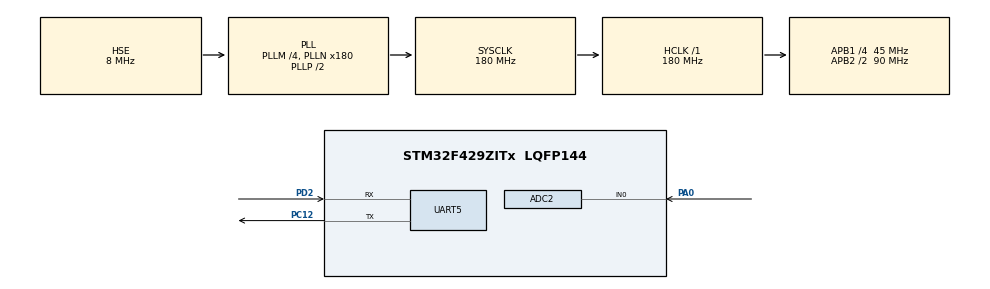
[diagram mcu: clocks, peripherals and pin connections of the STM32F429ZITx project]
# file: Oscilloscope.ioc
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ADC1.Channel-0\#ChannelRegularConversion=ADC_CHANNEL_VREFINT
ADC1.NbrOfConversionFlag=1
ADC1.Rank-0\#ChannelRegularConversion=1
ADC1.Resolution=ADC_RESOLUTION_10B
ADC1.SamplingTime-0\#ChannelRegularConversion=ADC_SAMPLETIME_3CYCLES
ADC1.master=1
ADC2.Channel-0\#ChannelRegularConversion=ADC_CHANNEL_0
ADC2.ContinuousConvMode=ENABLE
ADC2.DMAContinuousRequests=ENABLE
ADC2.NbrOfConversionFlag=1
ADC2.Rank-0\#ChannelRegularConversion=1
ADC2.Resolution=ADC_RESOLUTION_8B
ADC2.SamplingTime-0\#ChannelRegularConversion=ADC_SAMPLETIME_3CYCLES
Dma.ADC2.0.Direction=DMA_PERIPH_TO_MEMORY
Dma.ADC2.0.FIFOMode=DMA_FIFOMODE_DISABLE
Dma.ADC2.0.Instance=DMA2_Stream2
Dma.ADC2.0.MemDataAlignment=DMA_MDATAALIGN_HALFWORD
Dma.ADC2.0.MemInc=DMA_MINC_ENABLE
Dma.ADC2.0.Mode=DMA_CIRCULAR
Dma.ADC2.0.PeriphDataAlignment=DMA_PDATAALIGN_HALFWORD
Dma.ADC2.0.PeriphInc=DMA_PINC_DISABLE
Dma.ADC2.0.Priority=DMA_PRIORITY_LOW
Dma.Request0=ADC2
Mcu.Family=STM32F4
Mcu.Name=STM32F429ZITx
Mcu.Package=LQFP144
NVIC.DMA2_Stream2_IRQn=true\:0\:0\:false\:false\:true\:false\:true
NVIC.PriorityGroup=NVIC_PRIORITYGROUP_4
PA0/WKUP.Signal=ADCx_IN0
PC12.Mode=Asynchronous
PC12.Signal=UART5_TX
PD2.Mode=Asynchronous
PD2.Signal=UART5_RX
PH0/OSC_IN.Mode=HSE-External-Oscillator
PH0/OSC_IN.Signal=RCC_OSC_IN
PH1/OSC_OUT.Mode=HSE-External-Oscillator
PH1/OSC_OUT.Signal=RCC_OSC_OUT
ProjectManager.HeapSize=0x200
ProjectManager.StackSize=0x400
ProjectManager.TargetToolchain=MDK-ARM V5.27
RCC.48MHZClocksFreq_Value=90000000
RCC.AHBFreq_Value=180000000
RCC.APB1CLKDivider=RCC_HCLK_DIV4
RCC.APB1Freq_Value=45000000
RCC.APB1TimFreq_Value=90000000
RCC.APB2CLKDivider=RCC_HCLK_DIV2
RCC.APB2Freq_Value=90000000
RCC.APB2TimFreq_Value=180000000
RCC.CortexFreq_Value=180000000
RCC.HCLKFreq_Value=180000000
RCC.HSE_VALUE=8000000
RCC.HSI_VALUE=16000000
RCC.LSE_VALUE=32768
RCC.PLLM=4
RCC.PLLN=180
RCC.PLLSourceVirtual=RCC_PLLSOURCE_HSE
RCC.SYSCLKFreq_VALUE=180000000
RCC.SYSCLKSource=RCC_SYSCLKSOURCE_PLLCLK
RCC.VCOOutputFreq_Value=360000000
SH.ADCx_IN0.0=ADC2_IN0,IN0
UART5.VirtualMode=Asynchronous
VP_ADC1_Vref_Input.Mode=IN-Vrefint
board=custom

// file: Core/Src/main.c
/* USER CODE BEGIN Header */
/**
  ******************************************************************************
  * @file           : main.c
  * @brief          : Main program body
  ******************************************************************************
  * @attention
  *
  * <h2><center>&copy; Copyright (c) 2020 STMicroelectronics.
  * All rights reserved.</center></h2>
  *
  * This software component is licensed by ST under BSD 3-Clause license,
  * the "License"; You may not use this file except in compliance with the
  * License. You may obtain a copy of the License at:
  *                        opensource.org/licenses/BSD-3-Clause
  *
  ******************************************************************************
  */
/* USER CODE END Header */
#include "main.h"

/* USER CODE BEGIN PTD */

uint8_t adc1Val, adc2Val[1] = {0}, OscVal[1024];
char tx_buffer[50];
int a = 0;
float Vrefin, Vadc;

/* USER CODE END PTD */

/* USER CODE BEGIN PD */

#define 		VREFIN_CAL		((uint16_t*)((uint32_t)0x1FFF7A2A))

/* USER CODE END PD */

ADC_HandleTypeDef hadc1;
ADC_HandleTypeDef hadc2;
DMA_HandleTypeDef hdma_adc2;

UART_HandleTypeDef huart5;

void SystemClock_Config(void);
static void MX_GPIO_Init(void);
static void MX_DMA_Init(void);
static void MX_ADC1_Init(void);
static void MX_ADC2_Init(void);
static void MX_UART5_Init(void);

/* USER CODE BEGIN 0 */

void ReadADC(){

		for(uint16_t i = 0 ; i<1024; i++){

			OscVal[i] = adc2Val[0];

		}

}

/* USER CODE END 0 */

int main(void)
{

  /* MCU Configuration--------------------------------------------------------*/

  /* Reset of all peripherals, Initializes the Flash interface and the Systick. */
  HAL_Init();

  /* Configure the system clock */
  SystemClock_Config();

  /* Initialize all configured peripherals */
  MX_GPIO_Init();
  MX_DMA_Init();
  MX_ADC1_Init();
  MX_ADC2_Init();
  MX_UART5_Init();
  /* USER CODE BEGIN 2 */

	HAL_ADC_Start(&hadc1);

	if(HAL_ADC_PollForConversion(&hadc1,100) == HAL_OK){

			adc1Val = HAL_ADC_GetValue(&hadc1);

	}

	Vrefin = 3.3 * (*VREFIN_CAL) / adc1Val;

	HAL_ADC_Stop(&hadc1);

	HAL_ADC_Start_DMA(&hadc2, (uint32_t*)adc2Val, 1);

  /* USER CODE END 2 */

  /* Infinite loop */
  while (1)
  {

    /* USER CODE BEGIN 3 */

		a++;

			ReadADC();

		/*for(uint16_t i = 0; i<1024; i++){

		HAL_UART_Transmit(&huart5, (uint8_t*)tx_buffer, sprintf(tx_buffer, "Ali"), 500);

		}*/
  }
  /* USER CODE END 3 */
}

void SystemClock_Config(void)
{
  RCC_OscInitTypeDef RCC_OscInitStruct = {0};
  RCC_ClkInitTypeDef RCC_ClkInitStruct = {0};

  /** Configure the main internal regulator output voltage
  */
  __HAL_RCC_PWR_CLK_ENABLE();
  __HAL_PWR_VOLTAGESCALING_CONFIG(PWR_REGULATOR_VOLTAGE_SCALE1);
  /** Initializes the RCC Oscillators according to the specified parameters
  * in the RCC_OscInitTypeDef structure.
  */
  RCC_OscInitStruct.OscillatorType = RCC_OSCILLATORTYPE_HSE;
  RCC_OscInitStruct.HSEState = RCC_HSE_ON;
  RCC_OscInitStruct.PLL.PLLState = RCC_PLL_ON;
  RCC_OscInitStruct.PLL.PLLSource = RCC_PLLSOURCE_HSE;
  RCC_OscInitStruct.PLL.PLLM = 4;
  RCC_OscInitStruct.PLL.PLLN = 180;
  RCC_OscInitStruct.PLL.PLLP = RCC_PLLP_DIV2;
  RCC_OscInitStruct.PLL.PLLQ = 4;
  if (HAL_RCC_OscConfig(&RCC_OscInitStruct) != HAL_OK)
  {
    Error_Handler();
  }
  /** Activate the Over-Drive mode
  */
  if (HAL_PWREx_EnableOverDrive() != HAL_OK)
  {
    Error_Handler();
  }
  /** Initializes the CPU, AHB and APB buses clocks
  */
  RCC_ClkInitStruct.ClockType = RCC_CLOCKTYPE_HCLK|RCC_CLOCKTYPE_SYSCLK
                              |RCC_CLOCKTYPE_PCLK1|RCC_CLOCKTYPE_PCLK2;
  RCC_ClkInitStruct.SYSCLKSource = RCC_SYSCLKSOURCE_PLLCLK;
  RCC_ClkInitStruct.AHBCLKDivider = RCC_SYSCLK_DIV1;
  RCC_ClkInitStruct.APB1CLKDivider = RCC_HCLK_DIV4;
  RCC_ClkInitStruct.APB2CLKDivider = RCC_HCLK_DIV2;

  if (HAL_RCC_ClockConfig(&RCC_ClkInitStruct, FLASH_LATENCY_5) != HAL_OK)
  {
    Error_Handler();
  }
}

static void MX_ADC1_Init(void)
{

  ADC_ChannelConfTypeDef sConfig = {0};

  /** Configure the global features of the ADC (Clock, Resolution, Data Alignment and number of conversion)
  */
  hadc1.Instance = ADC1;
  hadc1.Init.ClockPrescaler = ADC_CLOCK_SYNC_PCLK_DIV4;
  hadc1.Init.Resolution = ADC_RESOLUTION_8B;
  hadc1.Init.ScanConvMode = DISABLE;
  hadc1.Init.ContinuousConvMode = DISABLE;
  hadc1.Init.DiscontinuousConvMode = DISABLE;
  hadc1.Init.ExternalTrigConvEdge = ADC_EXTERNALTRIGCONVEDGE_NONE;
  hadc1.Init.ExternalTrigConv = ADC_SOFTWARE_START;
  hadc1.Init.DataAlign = ADC_DATAALIGN_RIGHT;
  hadc1.Init.NbrOfConversion = 1;
  hadc1.Init.DMAContinuousRequests = DISABLE;
  hadc1.Init.EOCSelection = ADC_EOC_SINGLE_CONV;
  if (HAL_ADC_Init(&hadc1) != HAL_OK)
  {
    Error_Handler();
  }
  /** Configure for the selected ADC regular channel its corresponding rank in the sequencer and its sample time.
  */
  sConfig.Channel = ADC_CHANNEL_VREFINT;
  sConfig.Rank = 1;
  sConfig.SamplingTime = ADC_SAMPLETIME_3CYCLES;
  if (HAL_ADC_ConfigChannel(&hadc1, &sConfig) != HAL_OK)
  {
    Error_Handler();
  }

}

static void MX_ADC2_Init(void)
{

  ADC_ChannelConfTypeDef sConfig = {0};

  /** Configure the global features of the ADC (Clock, Resolution, Data Alignment and number of conversion)
  */
  hadc2.Instance = ADC2;
  hadc2.Init.ClockPrescaler = ADC_CLOCK_SYNC_PCLK_DIV4;
  hadc2.Init.Resolution = ADC_RESOLUTION_8B;
  hadc2.Init.ScanConvMode = DISABLE;
  hadc2.Init.ContinuousConvMode = ENABLE;
  hadc2.Init.DiscontinuousConvMode = DISABLE;
  hadc2.Init.ExternalTrigConvEdge = ADC_EXTERNALTRIGCONVEDGE_NONE;
  hadc2.Init.ExternalTrigConv = ADC_SOFTWARE_START;
  hadc2.Init.DataAlign = ADC_DATAALIGN_RIGHT;
  hadc2.Init.NbrOfConversion = 1;
  hadc2.Init.DMAContinuousRequests = ENABLE;
  hadc2.Init.EOCSelection = ADC_EOC_SINGLE_CONV;
  if (HAL_ADC_Init(&hadc2) != HAL_OK)
  {
    Error_Handler();
  }
  /** Configure for the selected ADC regular channel its corresponding rank in the sequencer and its sample time.
  */
  sConfig.Channel = ADC_CHANNEL_0;
  sConfig.Rank = 1;
  sConfig.SamplingTime = ADC_SAMPLETIME_15CYCLES;
  if (HAL_ADC_ConfigChannel(&hadc2, &sConfig) != HAL_OK)
  {
    Error_Handler();
  }

}

static void MX_UART5_Init(void)
{

  huart5.Instance = UART5;
  huart5.Init.BaudRate = 115200;
  huart5.Init.WordLength = UART_WORDLENGTH_8B;
  huart5.Init.StopBits = UART_STOPBITS_1;
  huart5.Init.Parity = UART_PARITY_NONE;
  huart5.Init.Mode = UART_MODE_TX_RX;
  huart5.Init.HwFlowCtl = UART_HWCONTROL_NONE;
  huart5.Init.OverSampling = UART_OVERSAMPLING_16;
  if (HAL_UART_Init(&huart5) != HAL_OK)
  {
    Error_Handler();
  }

}

static void MX_DMA_Init(void)
{

  /* DMA controller clock enable */
  __HAL_RCC_DMA2_CLK_ENABLE();

  /* DMA interrupt init */
  /* DMA2_Stream2_IRQn interrupt configuration */
  HAL_NVIC_SetPriority(DMA2_Stream2_IRQn, 0, 0);
  HAL_NVIC_EnableIRQ(DMA2_Stream2_IRQn);

}

static void MX_GPIO_Init(void)
{

  /* GPIO Ports Clock Enable */
  __HAL_RCC_GPIOH_CLK_ENABLE();
  __HAL_RCC_GPIOA_CLK_ENABLE();
  __HAL_RCC_GPIOC_CLK_ENABLE();
  __HAL_RCC_GPIOD_CLK_ENABLE();

}

void Error_Handler(void)
{
}

/************************ (C) COPYRIGHT STMicroelectronics *****END OF FILE****/
